# ble_rfcore_rdbell_secure register map
Vendor: Texas Instruments
Peripheral module from a debugger description file (folder CC35X1E).
Registers are 32-bit, read-write, reset 0x0 unless marked. A register's access mark holds for its fields unless they carry their own. Offsets are as the file gives them; lines under a group give offsets from that group; [hi:lo] are bit positions; {n}, {i} and the like mark numbered series; 'fields as' and 'values as' point back to an identical list; <NAME> marks a mode.

## ble_rfcore_rdbell_secure
0x00 cmdr — Doorbell Command Register
  [31:0] CMD — Command register. Raises an interrupt to the Command and packet engine (CPE) upon write.
0x04 cmdsta ro — Doorbell Command Status Register
  [31:0] STAT — Status of the last command used
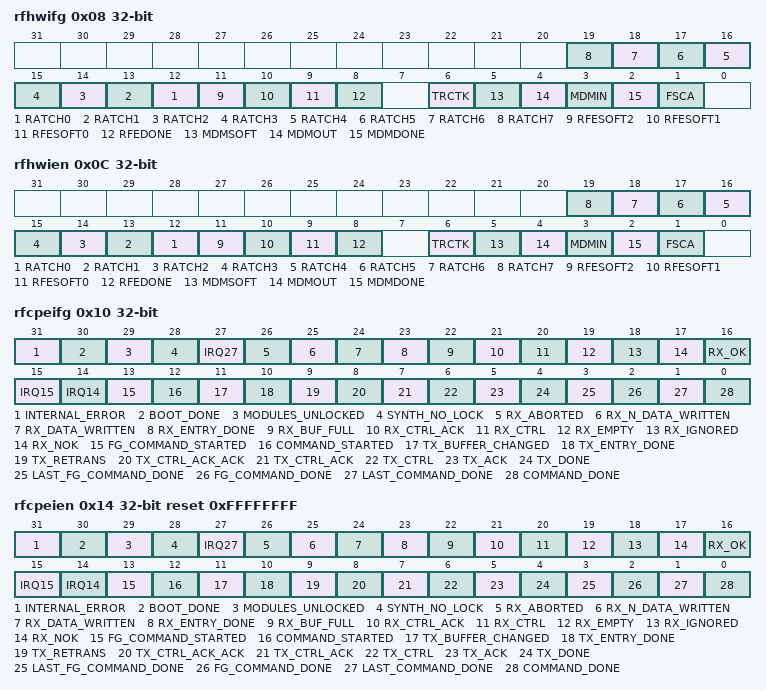
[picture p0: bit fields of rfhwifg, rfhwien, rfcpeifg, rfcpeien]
0x08 rfhwifg access per field — Interrupt Flags From RF Hardware Modules
  [n+12] RATCH{n} rw (n=0..7) — Radio timer channel {n} interrupt flag. Write zero to clear flag. Write to one has no effect.
  [11] RFESOFT2 rw — RF engine software defined interrupt 2 flag. Write zero to clear flag. Write to one has no effect.
  [10] RFESOFT1 rw — RF engine software defined interrupt 1 flag. Write zero to clear flag. Write to one has no effect.
  [9] RFESOFT0 rw — RF engine software defined interrupt 0 flag. Write zero to clear flag. Write to one has no effect.
  [8] RFEDONE rw — RF engine command done interrupt flag. Write zero to clear flag. Write to one has no effect.
  [6] TRCTK rw — Debug tracer system tick interrupt flag. Write zero to clear flag. Write to one has no effect.
  [5] MDMSOFT rw — Modem software defined interrupt flag. Write zero to clear flag. Write to one has no effect.
  [4] MDMOUT rw — Modem FIFO output interrupt flag. Write zero to clear flag. Write to one has no effect.
  [3] MDMIN rw — Modem FIFO input interrupt flag. Write zero to clear flag. Write to one has no effect.
  [2] MDMDONE rw — Modem command done interrupt flag. Write zero to clear flag. Write to one has no effect.
  [1] FSCA rw — Frequency synthesizer calibration accelerator interrupt flag. Write zero to clear flag. Write to one has no effect.
0x0C rfhwien access per field — Interrupt Enable For RF Hardware Modules
  [n+12] RATCH{n} rw (n=0..7) — Interrupt enable for RFHWIFG.RATCH{n}.
  [11] RFESOFT2 rw — Interrupt enable for RFHWIFG.RFESOFT2.
  [10] RFESOFT1 rw — Interrupt enable for RFHWIFG.RFESOFT1.
  [9] RFESOFT0 rw — Interrupt enable for RFHWIFG.RFESOFT0.
  [8] RFEDONE rw — Interrupt enable for RFHWIFG.RFEDONE.
  [6] TRCTK rw — Interrupt enable for RFHWIFG.TRCTK.
  [5] MDMSOFT rw — Interrupt enable for RFHWIFG.MDMSOFT.
  [4] MDMOUT rw — Interrupt enable for RFHWIFG.MDMOUT.
  [3] MDMIN rw — Interrupt enable for RFHWIFG.MDMIN.
  [2] MDMDONE rw — Interrupt enable for RFHWIFG.MDMDONE.
  [1] FSCA rw — Interrupt enable for RFHWIFG.FSCA.
0x10 rfcpeifg — Interrupt Flags For Command and Packet Engine Generated Interrupts
  [31] INTERNAL_ERROR — Interrupt flag 31. The command and packet engine (CPE) has observed an unexpected error. A reset of the CPE is needed. This can be done by switching the RF Core power domain off and on in PRCM:PDCTL1RFC. Write zero to clear flag. Write to one has no effect.
  [30] BOOT_DONE — Interrupt flag 30. The command and packet engine (CPE) boot is finished. Write zero to clear flag. Write to one has no effect.
  [29] MODULES_UNLOCKED — Interrupt flag 29. As part of command and packet engine (CPE) boot process, it has opened access to RF Core modules and memories. Write zero to clear flag. Write to one has no effect.
  [28] SYNTH_NO_LOCK — Interrupt flag 28. The phase-locked loop in frequency synthesizer has reported loss of lock. Write zero to clear flag. Write to one has no effect.
  [27] IRQ27 — Interrupt flag 27. Write zero to clear flag. Write to one has no effect.
  [26] RX_ABORTED — Interrupt flag 26. Packet reception stopped before packet was done. Write zero to clear flag. Write to one has no effect.
  [25] RX_N_DATA_WRITTEN — Interrupt flag 25. Specified number of bytes written to partial read Rx buffer. Write zero to clear flag. Write to one has no effect.
  [24] RX_DATA_WRITTEN — Interrupt flag 24. Data written to partial read Rx buffer. Write zero to clear flag. Write to one has no effect.
  [23] RX_ENTRY_DONE — Interrupt flag 23. Rx queue data entry changing state to finished. Write zero to clear flag. Write to one has no effect.
  [22] RX_BUF_FULL — Interrupt flag 22. Packet received that did not fit in Rx queue. BLE mode: Packet received that did not fit in the Rx queue. IEEE 802.15.4 mode: Frame received that did not fit in the Rx queue. Write zero to clear flag. Write to one has no effect.
  [21] RX_CTRL_ACK — Interrupt flag 21. BLE mode only: LL control packet received with CRC OK, not to be ignored, then acknowledgement sent. Write zero to clear flag. Write to one has no effect.
  [20] RX_CTRL — Interrupt flag 20. BLE mode only: LL control packet received with CRC OK, not to be ignored. Write zero to clear flag. Write to one has no effect.
  [19] RX_EMPTY — Interrupt flag 19. BLE mode only: Packet received with CRC OK, not to be ignored, no payload. Write zero to clear flag. Write to one has no effect.
  [18] RX_IGNORED — Interrupt flag 18. Packet received, but can be ignored. BLE mode: Packet received with CRC OK, but to be ignored. IEEE 802.15.4 mode: Frame received with ignore flag set. Write zero to clear flag. Write to one has no effect.
  [17] RX_NOK — Interrupt flag 17. Packet received with CRC error. BLE mode: Packet received with CRC error. IEEE 802.15.4 mode: Frame received with CRC error. Write zero to clear flag. Write to one has no effect.
  [16] RX_OK — Interrupt flag 16. Packet received correctly. BLE mode: Packet received with CRC OK, payload, and not to be ignored. IEEE 802.15.4 mode: Frame received with CRC OK. Write zero to clear flag. Write to one has no effect.
  [15] IRQ15 — Interrupt flag 15. Write zero to clear flag. Write to one has no effect.
  [14] IRQ14 — Interrupt flag 14. Write zero to clear flag. Write to one has no effect.
  [13] FG_COMMAND_STARTED — Interrupt flag 13. IEEE 802.15.4 mode only: A foreground radio operation command has gone into active state.
  [12] COMMAND_STARTED — Interrupt flag 12. A radio operation command has gone into active state.
  [11] TX_BUFFER_CHANGED — Interrupt flag 11. BLE mode only: A buffer change is complete after CMD_BLE_ADV_PAYLOAD. Write zero to clear flag. Write to one has no effect.
  [10] TX_ENTRY_DONE — Interrupt flag 10. Tx queue data entry state changed to finished. Write zero to clear flag. Write to one has no effect.
  [9] TX_RETRANS — Interrupt flag 9. BLE mode only: Packet retransmitted. Write zero to clear flag. Write to one has no effect.
  [8] TX_CTRL_ACK_ACK — Interrupt flag 8. BLE mode only: Acknowledgement received on a transmitted LL control packet, and acknowledgement transmitted for that packet. Write zero to clear flag. Write to one has no effect.
  [7] TX_CTRL_ACK — Interrupt flag 7. BLE mode: Acknowledgement received on a transmitted LL control packet. Write zero to clear flag. Write to one has no effect.
  [6] TX_CTRL — Interrupt flag 6. BLE mode: Transmitted LL control packet. Write zero to clear flag. Write to one has no effect.
  [5] TX_ACK — Interrupt flag 5. BLE mode: Acknowledgement received on a transmitted packet. IEEE 802.15.4 mode: Transmitted automatic ACK frame. Write zero to clear flag. Write to one has no effect.
  [4] TX_DONE — Interrupt flag 4. Packet transmitted. (BLE mode: A packet has been transmitted.) (IEEE 802.15.4 mode: A frame has been transmitted). Write zero to clear flag. Write to one has no effect.
  [3] LAST_FG_COMMAND_DONE — Interrupt flag 3. IEEE 802.15.4 mode only: The last foreground radio operation command in a chain of commands has finished. Write zero to clear flag. Write to one has no effect.
  [2] FG_COMMAND_DONE — Interrupt flag 2. IEEE 802.15.4 mode only: A foreground radio operation command has finished. Write zero to clear flag. Write to one has no effect.
  [1] LAST_COMMAND_DONE — Interrupt flag 1. The last radio operation command in a chain of commands has finished. (IEEE 802.15.4 mode: The last background level radio operation command in a chain of commands has finished.) Write zero to clear flag. Write to one has no effect.
  [0] COMMAND_DONE — Interrupt flag 0. A radio operation has finished. (IEEE 802.15.4 mode: A background level radio operation command has finished.) Write zero to clear flag. Write to one has no effect.
0x14 rfcpeien reset 0xFFFFFFFF — Interrupt Enable For Command and Packet Engine Generated Interrupts
  [31] INTERNAL_ERROR — Interrupt enable for RFCPEIFG.INTERNAL_ERROR.
  [30] BOOT_DONE — Interrupt enable for RFCPEIFG.BOOT_DONE.
  [29] MODULES_UNLOCKED — Interrupt enable for RFCPEIFG.MODULES_UNLOCKED.
  [28] SYNTH_NO_LOCK — Interrupt enable for RFCPEIFG.SYNTH_NO_LOCK.
  [27] IRQ27 — Interrupt enable for RFCPEIFG.IRQ27.
  [26] RX_ABORTED — Interrupt enable for RFCPEIFG.RX_ABORTED.
  [25] RX_N_DATA_WRITTEN — Interrupt enable for RFCPEIFG.RX_N_DATA_WRITTEN.
  [24] RX_DATA_WRITTEN — Interrupt enable for RFCPEIFG.RX_DATA_WRITTEN.
  [23] RX_ENTRY_DONE — Interrupt enable for RFCPEIFG.RX_ENTRY_DONE.
  [22] RX_BUF_FULL — Interrupt enable for RFCPEIFG.RX_BUF_FULL.
  [21] RX_CTRL_ACK — Interrupt enable for RFCPEIFG.RX_CTRL_ACK.
  [20] RX_CTRL — Interrupt enable for RFCPEIFG.RX_CTRL.
  [19] RX_EMPTY — Interrupt enable for RFCPEIFG.RX_EMPTY.
  [18] RX_IGNORED — Interrupt enable for RFCPEIFG.RX_IGNORED.
  [17] RX_NOK — Interrupt enable for RFCPEIFG.RX_NOK.
  [16] RX_OK — Interrupt enable for RFCPEIFG.RX_OK.
  [15] IRQ15 — Interrupt enable for RFCPEIFG.IRQ15.
  [14] IRQ14 — Interrupt enable for RFCPEIFG.IRQ14.
  [13] FG_COMMAND_STARTED — Interrupt enable for RFCPEIFG.FG_COMMAND_STARTED.
  [12] COMMAND_STARTED — Interrupt enable for RFCPEIFG.COMMAND_STARTED.
  [11] TX_BUFFER_CHANGED — Interrupt enable for RFCPEIFG.TX_BUFFER_CHANGED.
  [10] TX_ENTRY_DONE — Interrupt enable for RFCPEIFG.TX_ENTRY_DONE.
  [9] TX_RETRANS — Interrupt enable for RFCPEIFG.TX_RETRANS.
  [8] TX_CTRL_ACK_ACK — Interrupt enable for RFCPEIFG.TX_CTRL_ACK_ACK.
  [7] TX_CTRL_ACK — Interrupt enable for RFCPEIFG.TX_CTRL_ACK.
  [6] TX_CTRL — Interrupt enable for RFCPEIFG.TX_CTRL.
  [5] TX_ACK — Interrupt enable for RFCPEIFG.TX_ACK.
  [4] TX_DONE — Interrupt enable for RFCPEIFG.TX_DONE.
  [3] LAST_FG_COMMAND_DONE — Interrupt enable for RFCPEIFG.LAST_FG_COMMAND_DONE.
  [2] FG_COMMAND_DONE — Interrupt enable for RFCPEIFG.FG_COMMAND_DONE.
  [1] LAST_COMMAND_DONE — Interrupt enable for RFCPEIFG.LAST_COMMAND_DONE.
  [0] COMMAND_DONE — Interrupt enable for RFCPEIFG.COMMAND_DONE.
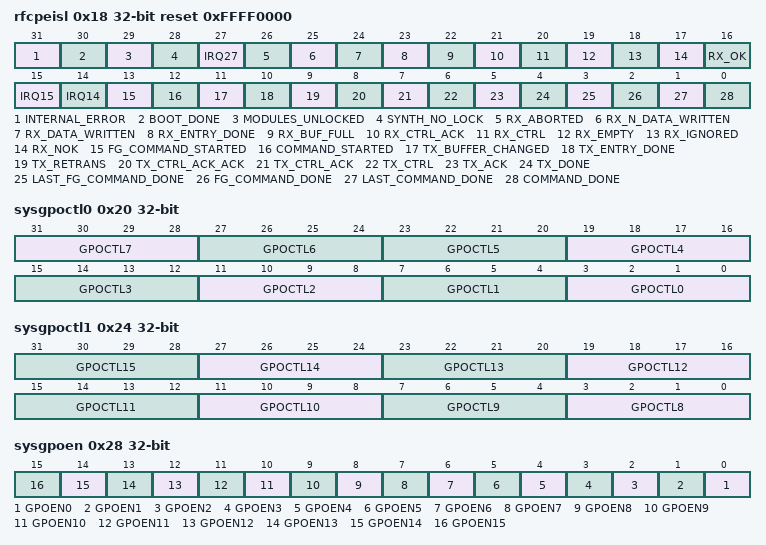
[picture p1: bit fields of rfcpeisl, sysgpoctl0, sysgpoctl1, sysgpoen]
0x18 rfcpeisl reset 0xFFFF0000 — Interrupt Vector Selection For Command and Packet Engine Generated Interrupts
  [all] fields
    0=CPE0 (Associate this interrupt line with INT_RF_CPE0 interrupt vector); 1=CPE1 (Associate this interrupt line with INT_RF_CPE1 interrupt vector)
  [31] INTERNAL_ERROR — Select which CPU interrupt vector the RFCPEIFG.INTERNAL_ERROR interrupt should use.
  [30] BOOT_DONE — Select which CPU interrupt vector the RFCPEIFG.BOOT_DONE interrupt should use.
  [29] MODULES_UNLOCKED — Select which CPU interrupt vector the RFCPEIFG.MODULES_UNLOCKED interrupt should use.
  [28] SYNTH_NO_LOCK — Select which CPU interrupt vector the RFCPEIFG.SYNTH_NO_LOCK interrupt should use.
  [27] IRQ27 — Select which CPU interrupt vector the RFCPEIFG.IRQ27 interrupt should use.
  [26] RX_ABORTED — Select which CPU interrupt vector the RFCPEIFG.RX_ABORTED interrupt should use.
  [25] RX_N_DATA_WRITTEN — Select which CPU interrupt vector the RFCPEIFG.RX_N_DATA_WRITTEN interrupt should use.
  [24] RX_DATA_WRITTEN — Select which CPU interrupt vector the RFCPEIFG.RX_DATA_WRITTEN interrupt should use.
  [23] RX_ENTRY_DONE — Select which CPU interrupt vector the RFCPEIFG.RX_ENTRY_DONE interrupt should use.
  [22] RX_BUF_FULL — Select which CPU interrupt vector the RFCPEIFG.RX_BUF_FULL interrupt should use.
  [21] RX_CTRL_ACK — Select which CPU interrupt vector the RFCPEIFG.RX_CTRL_ACK interrupt should use.
  [20] RX_CTRL — Select which CPU interrupt vector the RFCPEIFG.RX_CTRL interrupt should use.
  [19] RX_EMPTY — Select which CPU interrupt vector the RFCPEIFG.RX_EMPTY interrupt should use.
  [18] RX_IGNORED — Select which CPU interrupt vector the RFCPEIFG.RX_IGNORED interrupt should use.
  [17] RX_NOK — Select which CPU interrupt vector the RFCPEIFG.RX_NOK interrupt should use.
  [16] RX_OK — Select which CPU interrupt vector the RFCPEIFG.RX_OK interrupt should use.
  [15] IRQ15 — Select which CPU interrupt vector the RFCPEIFG.IRQ15 interrupt should use.
  [14] IRQ14 — Select which CPU interrupt vector the RFCPEIFG.IRQ14 interrupt should use.
  [13] FG_COMMAND_STARTED — Select which CPU interrupt vector the RFCPEIFG.FG_COMMAND_STARTED interrupt should use.
  [12] COMMAND_STARTED — Select which CPU interrupt vector the RFCPEIFG.COMMAND_STARTED interrupt should use.
  [11] TX_BUFFER_CHANGED — Select which CPU interrupt vector the RFCPEIFG.TX_BUFFER_CHANGED interrupt should use.
  [10] TX_ENTRY_DONE — Select which CPU interrupt vector the RFCPEIFG.TX_ENTRY_DONE interrupt should use.
  [9] TX_RETRANS — Select which CPU interrupt vector the RFCPEIFG.TX_RETRANS interrupt should use.
  [8] TX_CTRL_ACK_ACK — Select which CPU interrupt vector the RFCPEIFG.TX_CTRL_ACK_ACK interrupt should use.
  [7] TX_CTRL_ACK — Select which CPU interrupt vector the RFCPEIFG.TX_CTRL_ACK interrupt should use.
  [6] TX_CTRL — Select which CPU interrupt vector the RFCPEIFG.TX_CTRL interrupt should use.
  [5] TX_ACK — Select which CPU interrupt vector the RFCPEIFG.TX_ACK interrupt should use.
  [4] TX_DONE — Select which CPU interrupt vector the RFCPEIFG.TX_DONE interrupt should use.
  [3] LAST_FG_COMMAND_DONE — Select which CPU interrupt vector the RFCPEIFG.LAST_FG_COMMAND_DONE interrupt should use.
  [2] FG_COMMAND_DONE — Select which CPU interrupt vector the RFCPEIFG.FG_COMMAND_DONE interrupt should use.
  [1] LAST_COMMAND_DONE — Select which CPU interrupt vector the RFCPEIFG.LAST_COMMAND_DONE interrupt should use.
  [0] COMMAND_DONE — Select which CPU interrupt vector the RFCPEIFG.COMMAND_DONE interrupt should use.
0x1C rfackifg access per field — Doorbell Command Acknowledgement Interrupt Flag
  [0] ACKFLAG rw — Interrupt flag for Command ACK
0x20 sysgpoctl0 — RF Core General Purpose Output Control 0
  [all] fields
    {v}=CPEGPO{v} (CPE GPO line {v}) (v=0..3); {v}=RFEGPO{v-8} (RFE GPO line {v-8}) (v=8..11); {v}=RATGPO{v-12} (RAT GPO line {v-12}) (v=12..15); {v}=MCEGPO{v-4} (MCE GPO line {v-4}) (v=4..7)
  [31:28] GPOCTL7 — RF Core GPO control bit 7. Selects which signal to output on the RF Core GPO line 7.
  [27:24] GPOCTL6 — RF Core GPO control bit 5. Selects which signal to output on the RF Core GPO line 6.
  [4n+3:4n] GPOCTL{n} (n=0..5) — RF Core GPO control bit {n}. Selects which signal to output on the RF Core GPO line {n}.
0x24 sysgpoctl1 — RF Core General Purpose Output Control 1
  [all] fields
    values as the fields of sysgpoctl0
  [4n-29:4n-32] GPOCTL{n} (n=8..15) — RF Core GPO control bit {n}. Selects which signal to output on the RF Core GPO line {n}.
0x28 sysgpoen access per field — RF Core General Purpose Output ENABLE
  [n] GPOEN{n} rw (n=0..15) — RF Core GPO bit {n} ENABLE.
